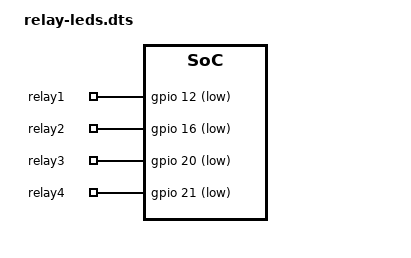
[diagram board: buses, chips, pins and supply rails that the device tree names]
/dts-v1/;
/plugin/;
/* dtc -I dts -O dtb relay-leds.dts > /boot/overlays/relay-leds.dtbo */
/ {
	fragment@0 {
		target = <&leds>;
		__overlay__ {
			compatible = "gpio-leds";
			relay1: relay@1 {
				label = "relay1";
				gpios = <&gpio 12 1>; /* 0 = active low, 1 = active high */
				linux,default-trigger = "none"; /* default-on */
			};
			relay2: relay@2 {
				label = "relay2";
				gpios = <&gpio 16 1>;
			};
			relay3: relay@3 {
				label = "relay3";
				gpios = <&gpio 20 1>;
			};
			relay4: relay@4 {
				label = "relay4";
				gpios = <&gpio 21 1>;
			};
		};
	};
};
